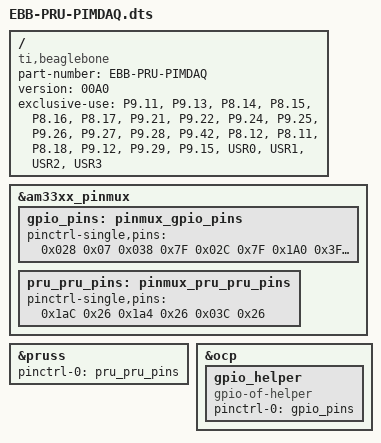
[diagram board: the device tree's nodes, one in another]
/* Device Tree Overlay for enabling the pins that are used in Chapter 13
* This overlay is based on the BB-PRU-01 overlay
* Written by Derek Molloy for the book "Exploring BeagleBone: Tools and 
* Techniques for Building with Embedded Linux" by John Wiley & Sons, 2014
* ISBN 9781118935125. Please see the file README.md in the repository root 
* directory for copyright and GNU GPLv3 license information.
*/
/dts-v1/;
/plugin/;

/ {
   compatible = "ti,beaglebone", "ti,beaglebone-black";

   part-number = "EBB-PRU-PIMDAQ";
   version = "00A0";

   /* This overlay uses the following resources */
   exclusive-use =
         "P9.11","P9.13","P8.14","P8.15","P8.16","P8.17","P9.21","P9.22","P9.24","P9.25","P9.26","P9.27","P9.28","P9.42",
	 "P8.12","P8.11","P8.18","P9.12","P9.29","P9.15","USR0","USR1","USR2","USR3";

   fragment@0 {
      target = <&am33xx_pinmux>;
      __overlay__ {

         gpio_pins: pinmux_gpio_pins {         // The GPIO pins
            pinctrl-single,pins = <
		0x028 0x07  // P8_14 MODE7 | OUTPUT | GPIO0_26 fast pull-down
		0x038 0x7F  // P8_16 MODE7 | INPUT | GPIO1_14 fast pull-up
		0x02C 0x7F  // P8_17 MODE7 | INPUT | GPIO0_27 fast pull-up
		0x1A0 0x3F  // NA    MODE7 | INPUT | GPIO3_18 slow pull-up
               	0x070 0x26  // P9_11 MODE6 | INPUT | UART4_RXD pull-down
               	0x074 0x06  // P9_13 MODE6 | OUTPUT | UART4_TXD pull-down
		0x150 0x26  // P9_22 MODE6 | INPUT | UART2_RXD pull-down
               	0x154 0x06  // P9_21 MODE6 | OUTPUT | UART2_TXD pull-down
		0x164 0x78  // P9_42 MODE0 | INPUT | eCAP0 fast pull-up
		0x174 0x7C  // P9_24 MODE4 | INPUT | eCAP1 fast pull-up
		0x170 0x7C  // P9_26 MODE4 | INPUT | eCAP2 fast pull-up
		0x030 0x24  // P8_12 MODE7 | INPUT | GPIO1_12 pull-down
		0x034 0x24  // P8_11 MODE7 | INPUT | GPIO1_13 pull-down
		0x08C 0x57  // P8_18 MODE7 | OUTPUT |GPIO2_1 slow pull-up
		0x078 0x07  // P9_12 MODE7 | OUTPUT |GPIO1_28 fast pull-down
		0x07C 0x57  // P8_26 MODE7 | OUTPUT |GPIO1_29 slow pull-up
		0x040 0x57  // P9_15 MODE7 | OUTPUT |GPIO1_16 slow pull-up
		0x054 0x77  // USR0  MODE7 | INPUT |GPIO1_21 slow pull-up
		0x058 0x77  // USR1  MODE7 | INPUT |GPIO1_22 slow pull-up
		0x05C 0x17  // USR2  MODE7 | OUTPUT|GPIO1_23 fast pull-up
		0x060 0x17  // USR3  MODE7 | OUTPUT|GPIO1_24 fast pull-up
            >;
         };

         pru_pru_pins: pinmux_pru_pru_pins {   // The PRU pin modes
            pinctrl-single,pins = <
		0x1aC 0x26  // P9_25 pr1_pru0_pru_r31_7, MODE6 | INPUT | PRU
              	0x1a4 0x26  // P9_27 pr1_pru0_pru_r31_5, MODE6 | INPUT | PRU
               	0x03C 0x26  // P8_15 pr1_pru0_pru_r31_15, MODE6 | INPUT | PRU


            >;
         };
      };
   };

   fragment@1 {         // Enable the PRUSS
      target = <&pruss>;
      __overlay__ {
         status = "okay";
         pinctrl-names = "default";
         pinctrl-0 = <&pru_pru_pins>;
      };
   };

   fragment@2 {         // Enable the GPIOs
      target = <&ocp>;
      __overlay__ {
         gpio_helper {
            compatible = "gpio-of-helper";
            status = "okay";
            pinctrl-names = "default";
            pinctrl-0 = <&gpio_pins>;
         };
      };
   };
};
